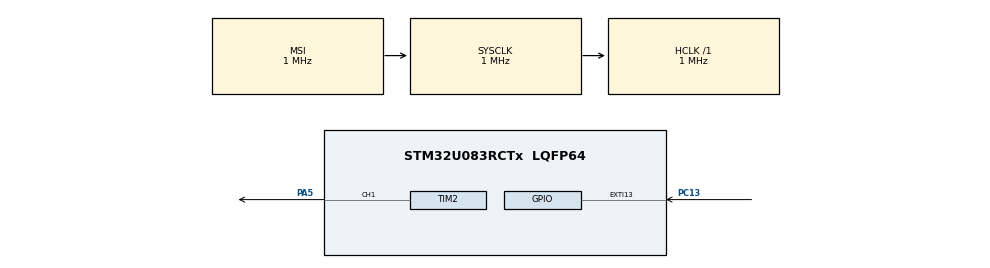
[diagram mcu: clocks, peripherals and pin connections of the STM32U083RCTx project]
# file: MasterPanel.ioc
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Dma.DMA_GENERATOR0.0.Direction=DMA_MEMORY_TO_PERIPH
Dma.DMA_GENERATOR0.0.EventEnable=DISABLE
Dma.DMA_GENERATOR0.0.Instance=DMA1_Channel1
Dma.DMA_GENERATOR0.0.MemDataAlignment=DMA_MDATAALIGN_WORD
Dma.DMA_GENERATOR0.0.MemInc=DMA_MINC_ENABLE
Dma.DMA_GENERATOR0.0.Mode=DMA_CIRCULAR
Dma.DMA_GENERATOR0.0.PeriphDataAlignment=DMA_PDATAALIGN_WORD
Dma.DMA_GENERATOR0.0.PeriphInc=DMA_PINC_DISABLE
Dma.DMA_GENERATOR0.0.Polarity=HAL_DMAMUX_REQ_GEN_FALLING
Dma.DMA_GENERATOR0.0.Priority=DMA_PRIORITY_LOW
Dma.DMA_GENERATOR0.0.RequestNumber=1
Dma.DMA_GENERATOR0.0.SignalID=HAL_DMAMUX1_REQ_GEN_EXTI13
Dma.DMA_GENERATOR0.0.SyncEnable=DISABLE
Dma.DMA_GENERATOR0.0.SyncPolarity=HAL_DMAMUX_SYNC_NO_EVENT
Dma.DMA_GENERATOR0.0.SyncRequestNumber=1
Dma.DMA_GENERATOR0.0.SyncSignalID=NONE
Dma.Request0=DMA_GENERATOR0
Mcu.Family=STM32U0
Mcu.Name=STM32U083RCTx
Mcu.Package=LQFP64
NVIC.PriorityGroup=NVIC_PRIORITYGROUP_2
PA5.Signal=S_TIM2_CH1_ETR
PC13.GPIO_ModeDefaultEXTI=GPIO_MODE_IT_FALLING
PC13.GPIO_PuPd=GPIO_PULLUP
PC13.Signal=GPXTI13
ProjectManager.HeapSize=0x200
ProjectManager.StackSize=0x400
ProjectManager.TargetToolchain=STM32CubeIDE
RCC.ADCFreq_Value=1000000
RCC.AHBFreq_Value=1000000
RCC.CortexFreq_Value=1000000
RCC.HCLKFreq_Value=1000000
RCC.HSE_VALUE=4000000
RCC.HSI48_VALUE=48000000
RCC.HSI_VALUE=16000000
RCC.LSE_VALUE=32768
RCC.MSIClockRangeVal=RCC_MSIRANGE_4
RCC.MSI_VALUE=1000000
RCC.SYSCLKFreq_VALUE=1000000
RCC.SYSCLKSource=RCC_SYSCLKSOURCE_MSI
RCC.USBFreq_Value=1000000
RCC.VCOOutputFreq_Value=64000000
SH.S_TIM2_CH1_ETR.0=TIM2_CH1,PWM Generation1 CH1
TIM2.Channel-PWM\ Generation1\ CH1=TIM_CHANNEL_1
TIM2.OCPolarity_1=TIM_OCPOLARITY_LOW
TIM2.Period=99
TIM2.Prescaler=49
VP_PWR_VS_SECSignals.Mode=Security/Privilege
VP_TIM2_VS_ClockSourceINT.Mode=Internal
board=custom

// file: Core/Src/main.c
/* USER CODE BEGIN Header */
/**
  ******************************************************************************
  * @file           : main.c
  * @brief          : Main program body
  ******************************************************************************
  * @attention
  *
  * Copyright (c) 2024 STMicroelectronics.
  * All rights reserved.
  *
  * This software is licensed under terms that can be found in the LICENSE file
  * in the root directory of this software component.
  * If no LICENSE file comes with this software, it is provided AS-IS.
  *
  ******************************************************************************
  */
/* USER CODE END Header */
#include "main.h"

TIM_HandleTypeDef htim2;

DMA_HandleTypeDef hdma_dma_generator0;
/* USER CODE BEGIN PV */
uint32_t SRC_Buffer_LED_PWM[4]  = {20, 40, 60, 0}; // define Low pulse width ~1ms, 2ms, 3ms and IDLE state
/* USER CODE END PV */

void SystemClock_Config(void);
static void MX_GPIO_Init(void);
static void MX_DMA_Init(void);
static void MX_TIM2_Init(void);

int main(void)
{

  /* MCU Configuration--------------------------------------------------------*/

  /* Reset of all peripherals, Initializes the Flash interface and the Systick. */
  HAL_Init();

  /* Configure the system clock */
  SystemClock_Config();

  /* Initialize all configured peripherals */
  MX_GPIO_Init();
  MX_DMA_Init();
  MX_TIM2_Init();
  /* USER CODE BEGIN 2 */
  /* Enable LP run mode */
 __HAL_RCC_PWR_CLK_ENABLE();
 HAL_PWREx_EnableLowPowerRunMode(); //we can do it as Sysclock <2MHz and enter in Sleep mode

 /*Drive LED and Generate Pulses*/
 HAL_TIM_PWM_Start(&htim2, TIM_CHANNEL_1);

 /*Enable DMAMUX*/
 HAL_DMAEx_EnableMuxRequestGenerator(&hdma_dma_generator0);

 /*Link PWM buffer and TIM2 capture/compare register through DMA_Ch1*/
 HAL_DMA_Start(&hdma_dma_generator0, (uint32_t)SRC_Buffer_LED_PWM, (uint32_t)&TIM2->CCR1, 4);

 /* Keep live DMA, SRAM, TIM2 and Ports only during SLEEP mode ~ 10uA/1MHz reduction*/
 WRITE_REG(RCC->AHBSMENR, RCC_AHBSMENR_DMA1SMEN|RCC_AHBSMENR_SRAM1SMEN);      // DMA, SRAM
 WRITE_REG(RCC->IOPSMENR, RCC_IOPSMENR_GPIOASMEN|RCC_IOPSMENR_GPIOCSMEN);     // GPIOA, GPIOC
 WRITE_REG(RCC->APBSMENR1, RCC_APBSMENR1_TIM2SMEN);                        // TIM2
 CLEAR_REG(RCC->APBSMENR2);

 /*Enter in LP SLEEP mode*/
 HAL_SuspendTick();
 HAL_PWREx_EnableFlashPowerDown(PWR_FLASHPD_LPSLEEP);
 HAL_PWR_EnterSLEEPMode(PWR_LOWPOWERREGULATOR_ON, PWR_SLEEPENTRY_WFI);
 HAL_ResumeTick();
  /* USER CODE END 2 */

  /* Infinite loop */
  while (1)
  {

  }
}

void SystemClock_Config(void)
{
  RCC_OscInitTypeDef RCC_OscInitStruct = {0};
  RCC_ClkInitTypeDef RCC_ClkInitStruct = {0};

  /** Configure the main internal regulator output voltage
  */
  HAL_PWREx_ControlVoltageScaling(PWR_REGULATOR_VOLTAGE_SCALE2);

  /** Initializes the RCC Oscillators according to the specified parameters
  * in the RCC_OscInitTypeDef structure.
  */
  RCC_OscInitStruct.OscillatorType = RCC_OSCILLATORTYPE_MSI;
  RCC_OscInitStruct.MSIState = RCC_MSI_ON;
  RCC_OscInitStruct.MSICalibrationValue = RCC_MSICALIBRATION_DEFAULT;
  RCC_OscInitStruct.MSIClockRange = RCC_MSIRANGE_4;
  RCC_OscInitStruct.PLL.PLLState = RCC_PLL_NONE;
  if (HAL_RCC_OscConfig(&RCC_OscInitStruct) != HAL_OK)
  {
    Error_Handler();
  }

  /** Initializes the CPU, AHB and APB buses clocks
  */
  RCC_ClkInitStruct.ClockType = RCC_CLOCKTYPE_HCLK|RCC_CLOCKTYPE_SYSCLK
                              |RCC_CLOCKTYPE_PCLK1;
  RCC_ClkInitStruct.SYSCLKSource = RCC_SYSCLKSOURCE_MSI;
  RCC_ClkInitStruct.AHBCLKDivider = RCC_SYSCLK_DIV1;
  RCC_ClkInitStruct.APB1CLKDivider = RCC_HCLK_DIV1;

  if (HAL_RCC_ClockConfig(&RCC_ClkInitStruct, FLASH_LATENCY_0) != HAL_OK)
  {
    Error_Handler();
  }
}

static void MX_TIM2_Init(void)
{

  TIM_ClockConfigTypeDef sClockSourceConfig = {0};
  TIM_MasterConfigTypeDef sMasterConfig = {0};
  TIM_OC_InitTypeDef sConfigOC = {0};

  htim2.Instance = TIM2;
  htim2.Init.Prescaler = 49;
  htim2.Init.CounterMode = TIM_COUNTERMODE_UP;
  htim2.Init.Period = 99;
  htim2.Init.ClockDivision = TIM_CLOCKDIVISION_DIV1;
  htim2.Init.AutoReloadPreload = TIM_AUTORELOAD_PRELOAD_DISABLE;
  if (HAL_TIM_Base_Init(&htim2) != HAL_OK)
  {
    Error_Handler();
  }
  sClockSourceConfig.ClockSource = TIM_CLOCKSOURCE_INTERNAL;
  if (HAL_TIM_ConfigClockSource(&htim2, &sClockSourceConfig) != HAL_OK)
  {
    Error_Handler();
  }
  if (HAL_TIM_PWM_Init(&htim2) != HAL_OK)
  {
    Error_Handler();
  }
  sMasterConfig.MasterOutputTrigger = TIM_TRGO_RESET;
  sMasterConfig.MasterSlaveMode = TIM_MASTERSLAVEMODE_DISABLE;
  if (HAL_TIMEx_MasterConfigSynchronization(&htim2, &sMasterConfig) != HAL_OK)
  {
    Error_Handler();
  }
  sConfigOC.OCMode = TIM_OCMODE_PWM1;
  sConfigOC.Pulse = 0;
  sConfigOC.OCPolarity = TIM_OCPOLARITY_LOW;
  sConfigOC.OCFastMode = TIM_OCFAST_DISABLE;
  if (HAL_TIM_PWM_ConfigChannel(&htim2, &sConfigOC, TIM_CHANNEL_1) != HAL_OK)
  {
    Error_Handler();
  }
  HAL_TIM_MspPostInit(&htim2);

}

static void MX_DMA_Init(void)
{

  /* Local variables */
  HAL_DMA_MuxRequestGeneratorConfigTypeDef pRequestGeneratorConfig = {0};

  /* DMA controller clock enable */
  __HAL_RCC_DMA1_CLK_ENABLE();

  /* Configure DMA request hdma_dma_generator0 on DMA1_Channel1 */
  hdma_dma_generator0.Instance = DMA1_Channel1;
  hdma_dma_generator0.Init.Request = DMA_REQUEST_GENERATOR0;
  hdma_dma_generator0.Init.Direction = DMA_MEMORY_TO_PERIPH;
  hdma_dma_generator0.Init.PeriphInc = DMA_PINC_DISABLE;
  hdma_dma_generator0.Init.MemInc = DMA_MINC_ENABLE;
  hdma_dma_generator0.Init.PeriphDataAlignment = DMA_PDATAALIGN_WORD;
  hdma_dma_generator0.Init.MemDataAlignment = DMA_MDATAALIGN_WORD;
  hdma_dma_generator0.Init.Mode = DMA_CIRCULAR;
  hdma_dma_generator0.Init.Priority = DMA_PRIORITY_LOW;
  if (HAL_DMA_Init(&hdma_dma_generator0) != HAL_OK)
  {
    Error_Handler( );
  }

  /* Configure the DMAMUX request generator for the selected DMA channel */
  pRequestGeneratorConfig.SignalID = HAL_DMAMUX1_REQ_GEN_EXTI13;
  pRequestGeneratorConfig.Polarity = HAL_DMAMUX_REQ_GEN_FALLING;
  pRequestGeneratorConfig.RequestNumber = 1;
  if (HAL_DMAEx_ConfigMuxRequestGenerator(&hdma_dma_generator0, &pRequestGeneratorConfig) != HAL_OK)
  {
    Error_Handler( );
  }

}

static void MX_GPIO_Init(void)
{
  GPIO_InitTypeDef GPIO_InitStruct = {0};

  /* GPIO Ports Clock Enable */
  __HAL_RCC_GPIOC_CLK_ENABLE();
  __HAL_RCC_GPIOA_CLK_ENABLE();

  /*Configure GPIO pin : PC13 */
  GPIO_InitStruct.Pin = GPIO_PIN_13;
  GPIO_InitStruct.Mode = GPIO_MODE_IT_FALLING;
  GPIO_InitStruct.Pull = GPIO_PULLUP;
  HAL_GPIO_Init(GPIOC, &GPIO_InitStruct);

}

void Error_Handler(void)
{
  __disable_irq();
  while (1)
  {
  }
}
